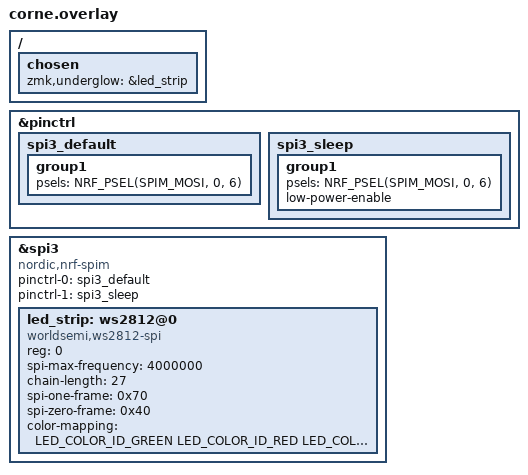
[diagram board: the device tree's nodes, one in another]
/*
 * Corne v3 RGB Override
 * This overrides the default corne shield to support per-key RGB
 */

#include <dt-bindings/led/led.h>

&pinctrl {
    spi3_default: spi3_default {
        group1 {
            psels = <NRF_PSEL(SPIM_MOSI, 0, 6)>;
        };
    };
    
    spi3_sleep: spi3_sleep {
        group1 {
            psels = <NRF_PSEL(SPIM_MOSI, 0, 6)>;
            low-power-enable;
        };
    };
};

&spi3 {
    compatible = "nordic,nrf-spim";
    status = "okay";
    
    pinctrl-0 = <&spi3_default>;
    pinctrl-1 = <&spi3_sleep>;
    pinctrl-names = "default", "sleep";
    
    led_strip: ws2812@0 {
        compatible = "worldsemi,ws2812-spi";
        reg = <0>;
        spi-max-frequency = <4000000>;
        
        /* 
         * Corne v3: 27 LEDs per side
         * 1-6: Underglow (WS2812, GRB)
         * 7-27: Per-key (SK6812-MINI-E, RGB)
         * 
         * NOTE: We can only use one color-mapping for the entire chain.
         */
        chain-length = <27>;
        
        spi-one-frame = <0x70>;
        spi-zero-frame = <0x40>;
        
        color-mapping = <LED_COLOR_ID_GREEN LED_COLOR_ID_RED LED_COLOR_ID_BLUE>;
    };
};

/ {
    chosen {
        zmk,underglow = &led_strip;
    };
};
